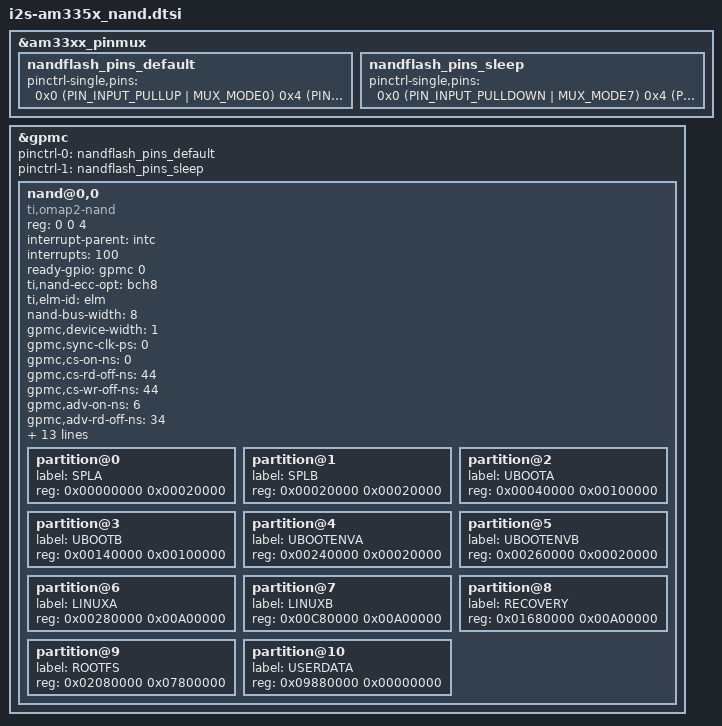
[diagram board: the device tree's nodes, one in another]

&am33xx_pinmux {

	nandflash_pins_default: nandflash_pins_default {
		pinctrl-single,pins = <
			0x0 (PIN_INPUT_PULLUP | MUX_MODE0)	/* gpmc_ad0.gpmc_ad0 */
			0x4 (PIN_INPUT_PULLUP | MUX_MODE0)	/* gpmc_ad1.gpmc_ad1 */
			0x8 (PIN_INPUT_PULLUP | MUX_MODE0)	/* gpmc_ad2.gpmc_ad2 */
			0xc (PIN_INPUT_PULLUP | MUX_MODE0)	/* gpmc_ad3.gpmc_ad3 */
			0x10 (PIN_INPUT_PULLUP | MUX_MODE0)	/* gpmc_ad4.gpmc_ad4 */
			0x14 (PIN_INPUT_PULLUP | MUX_MODE0)	/* gpmc_ad5.gpmc_ad5 */
			0x18 (PIN_INPUT_PULLUP | MUX_MODE0)	/* gpmc_ad6.gpmc_ad6 */
			0x1c (PIN_INPUT_PULLUP | MUX_MODE0)	/* gpmc_ad7.gpmc_ad7 */
			0x70 (PIN_INPUT_PULLUP | MUX_MODE0)	/* gpmc_wait0.gpmc_wait0 */
			0x74 (PIN_INPUT_PULLUP | MUX_MODE7)	/* gpmc_wpn.gpio0_30 */
			0x7c (PIN_OUTPUT | MUX_MODE0)		/* gpmc_csn0.gpmc_csn0  */
			0x90 (PIN_OUTPUT | MUX_MODE0)		/* gpmc_advn_ale.gpmc_advn_ale */
			0x94 (PIN_OUTPUT | MUX_MODE0)		/* gpmc_oen_ren.gpmc_oen_ren */
			0x98 (PIN_OUTPUT | MUX_MODE0)		/* gpmc_wen.gpmc_wen */
			0x9c (PIN_OUTPUT | MUX_MODE0)		/* gpmc_be0n_cle.gpmc_be0n_cle */
		>;
	};

	nandflash_pins_sleep: nandflash_pins_sleep {
		pinctrl-single,pins = <
			0x0 (PIN_INPUT_PULLDOWN | MUX_MODE7)
			0x4 (PIN_INPUT_PULLDOWN | MUX_MODE7)
			0x8 (PIN_INPUT_PULLDOWN | MUX_MODE7)
			0xc (PIN_INPUT_PULLDOWN | MUX_MODE7)
			0x10 (PIN_INPUT_PULLDOWN | MUX_MODE7)
			0x14 (PIN_INPUT_PULLDOWN | MUX_MODE7)
			0x18 (PIN_INPUT_PULLDOWN | MUX_MODE7)
			0x1c (PIN_INPUT_PULLDOWN | MUX_MODE7)
			0x70 (PIN_INPUT_PULLDOWN | MUX_MODE7)
			0x74 (PIN_INPUT_PULLDOWN | MUX_MODE7)
			0x7c (PIN_INPUT_PULLDOWN | MUX_MODE7)
			0x90 (PIN_INPUT_PULLDOWN | MUX_MODE7)
			0x94 (PIN_INPUT_PULLDOWN | MUX_MODE7)
			0x98 (PIN_INPUT_PULLDOWN | MUX_MODE7)
			0x9c (PIN_INPUT_PULLDOWN | MUX_MODE7)
		>;
	};

};
&gpmc {
	pinctrl-names = "default", "sleep";
	pinctrl-0 = <&nandflash_pins_default>;
	pinctrl-1 = <&nandflash_pins_sleep>;
	ranges = <0 0 0x08000000 0x1000000>;	/* CS0: 16MB for NAND */
	status = "okay";

	nand@0,0 {
		compatible = "ti,omap2-nand";
		reg = <0 0 4>; /* CS0, offset 0, IO size 4 */
		interrupt-parent = <&intc>;
		interrupts = <100>;
		ready-gpio = <&gpmc 0 GPIO_ACTIVE_HIGH>; /* gpmc_wait0 */
		ti,nand-ecc-opt = "bch8";
		ti,elm-id = <&elm>;
		nand-bus-width = <8>;
		gpmc,device-width = <1>;
		gpmc,sync-clk-ps = <0>;
		gpmc,cs-on-ns = <0>;
		gpmc,cs-rd-off-ns = <44>;
		gpmc,cs-wr-off-ns = <44>;
		gpmc,adv-on-ns = <6>;
		gpmc,adv-rd-off-ns = <34>;
		gpmc,adv-wr-off-ns = <44>;
		gpmc,we-on-ns = <0>;
		gpmc,we-off-ns = <40>;
		gpmc,oe-on-ns = <0>;
		gpmc,oe-off-ns = <54>;
		gpmc,access-ns = <64>;
		gpmc,rd-cycle-ns = <82>;
		gpmc,wr-cycle-ns = <82>;
		gpmc,bus-turnaround-ns = <0>;
		gpmc,cycle2cycle-delay-ns = <0>;
		gpmc,clk-activation-ns = <0>;
		gpmc,wr-access-ns = <40>;
		gpmc,wr-data-mux-bus-ns = <0>;
		/* MTD partition table */
		/* All SPL-* partitions are sized to minimal length
		 * which can be independently programmable. For
		 * NAND flash this is equal to size of erase-block */
		#address-cells = <1>;
		#size-cells = <1>;
		partition@0 {
			label = "SPLA";
			reg = <0x00000000 0x00020000>;
		};
		partition@1 {
			label = "SPLB";
			reg = <0x00020000 0x00020000>;
		};
		partition@2 {
			label = "UBOOTA";
			reg = <0x00040000 0x00100000>;
		};
		partition@3 {
			label = "UBOOTB";
			reg = <0x00140000 0x00100000>;
		};
		partition@4 {
			label = "UBOOTENVA";
			reg = <0x00240000 0x00020000>;
		};
		partition@5 {
			label = "UBOOTENVB";
			reg = <0x00260000 0x00020000>;
		};
		partition@6 {
			label = "LINUXA";
			reg = <0x00280000 0x00A00000>;
		};
		partition@7 {
			label = "LINUXB";
			reg = <0x00C80000 0x00A00000>;
		};
		partition@8 {
			label = "RECOVERY";
			reg = <0x01680000 0x00A00000>;
		};
		partition@9 {
			label = "ROOTFS";
			reg = <0x02080000 0x07800000>;
		};
		partition@10 {
			label = "USERDATA";
			reg = <0x09880000 0x00000000>;
		};		
	};
};
